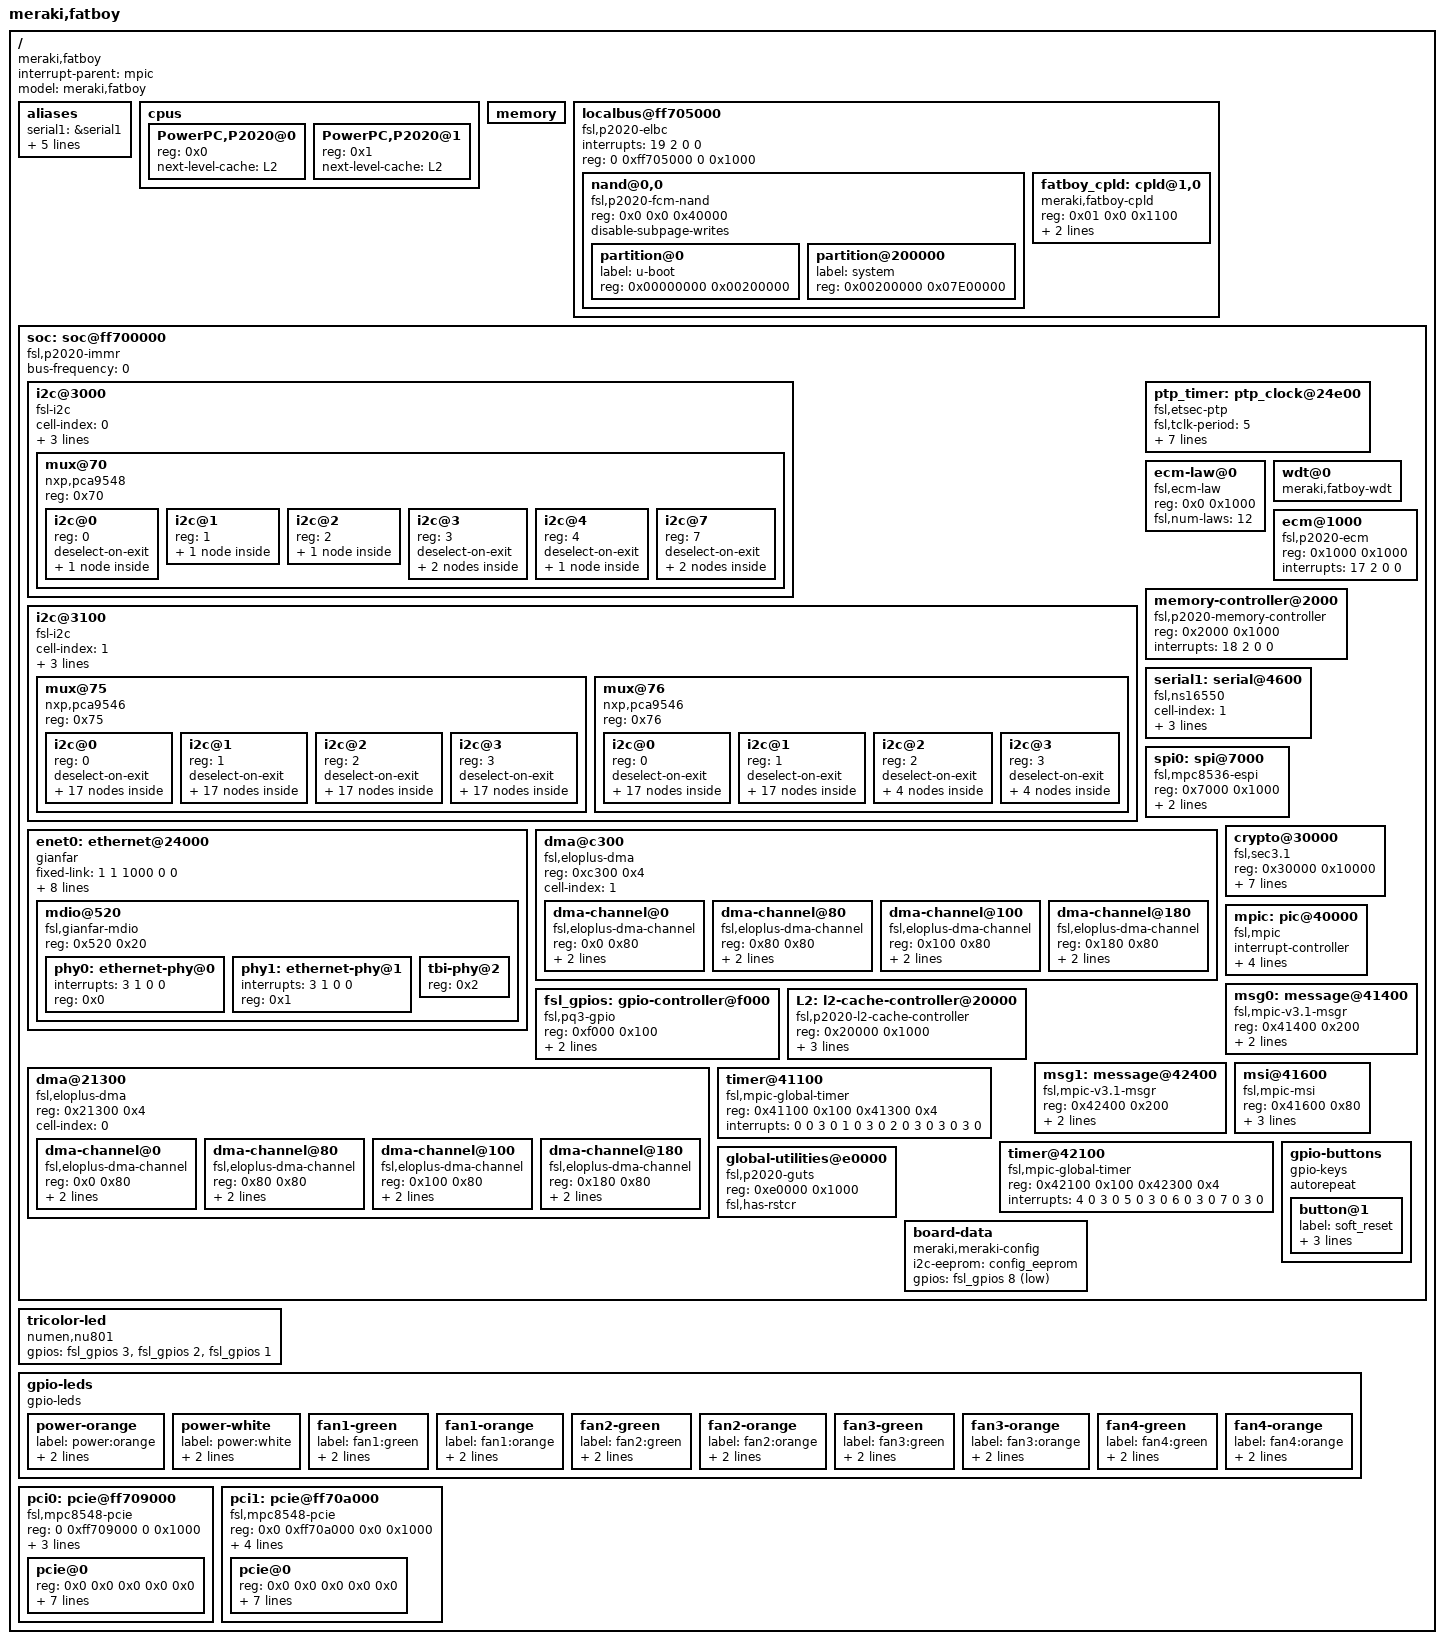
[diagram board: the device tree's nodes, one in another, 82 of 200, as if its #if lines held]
/*
 * Meraki MS420 Series Device Tree Source
 *
 * Copyright 2009-2012 Freescale Semiconductor Inc.
 * Copyright 2013 Cisco Systems, Inc.
 *
 * This program is free software; you can redistribute	it and/or modify it
 * under  the terms of	the GNU General	 Public License as published by the
 * Free Software Foundation;  either version 2 of the  License, or (at your
 * option) any later version.
 */

// Prevent the C preprocessor from expanding the pre-defined "linux" macro.
#ifdef linux
#undef linux
#endif

/dts-v1/;

/ {
	compatible = "meraki,fatboy";
	#address-cells = <2>;
	#size-cells = <2>;
	interrupt-parent = <&mpic>;
	model = "meraki,fatboy";

	aliases {
		serial1 = &serial1;  // U-Boot currently expects this to be aliased as serial1.
		ethernet0 = &enet0;
		pci0 = &pci0;
		pci1 = &pci1;
		mpic-msgr-block0 = &msg0;
		mpic-msgr-block1 = &msg1;
	};

	cpus {
		#address-cells = <1>;
		#size-cells = <0>;

		PowerPC,P2020@0 {
			device_type = "cpu";
			reg = <0x0>;
			next-level-cache = <&L2>;
		};

		PowerPC,P2020@1 {
			device_type = "cpu";
			reg = <0x1>;
			next-level-cache = <&L2>;
		};
	};

	memory {
		device_type = "memory";
	};

	localbus@ff705000 {
		#address-cells = <2>;
		#size-cells = <1>;
		interrupts = <19 2 0 0>;
		reg = <0 0xff705000 0 0x1000>;
		compatible = "fsl,p2020-elbc", "fsl,elbc", "simple-bus";

		ranges = <0x0 0x0 0x0 0xffa00000 0x40000
			  0x1 0x0 0x0 0xea000000 0x01100>;

		nand@0,0 {
			#address-cells = <1>;
			#size-cells = <1>;
			compatible = "fsl,p2020-fcm-nand", "fsl,elbc-fcm-nand";
			reg = <0x0 0x0 0x40000>;
                        disable-subpage-writes;

			partition@0 {
				label = "u-boot";
				reg = <0x00000000 0x00200000>;
			};

			partition@200000 {
				label = "system";
				reg = <0x00200000 0x07E00000>;
			};
                };

		fatboy_cpld: cpld@1,0 {
			compatible = "meraki,fatboy-cpld";
			reg = <0x01 0x0 0x1100>;

                        led-names = "fanstatus:orange", "fanstatus:green", "psu:orange", "psu:green";
		};
	};

	soc: soc@ff700000 {
		ranges = <0x0 0x0 0xff700000 0x100000>;
		#address-cells = <1>;
		#size-cells = <1>;
		device_type = "soc";
		compatible = "fsl,p2020-immr", "simple-bus";
		bus-frequency = <0>;

		i2c@3000 {
			#address-cells = <1>;
			#size-cells = <0>;
			cell-index = <0>;
			compatible = "fsl-i2c";
			reg = <0x3000 0x100>;
			interrupts = <43 2 0 0>;
			dfsrr;

			mux@70 {
				compatible = "nxp,pca9548";
				reg = <0x70>;
				#address-cells = <1>;
				#size-cells = <0>;

				i2c@0 {
					#address-cells = <1>;
					#size-cells = <0>;
					reg = <0>;
					deselect-on-exit;

					rtc@51 {
						compatible = "epson,rtc8564";
						reg = <0x51>;
					};
				};

				i2c@1 {
					#address-cells = <1>;
					#size-cells = <0>;
					reg = <1>;

					psu@3a {
						compatible = "ms420-psu";
						reg = <0x3a>;
						index = <2>;
					};
				};

				i2c@2 {
					#address-cells = <1>;
					#size-cells = <0>;
					reg = <2>;

					psu@39 {
						compatible = "ms420-psu";
						reg = <0x39>;
						index = <1>;
					};
				};

				i2c@3 {
					#address-cells = <1>;
					#size-cells = <0>;
					reg = <3>;
					deselect-on-exit;

					fan_led_gpios: gpio-controller@72 {
						#gpio-cells = <2>;
						compatible = "nxp,pca9538";
						reg = <0x72>;
						gpio-controller;
					};

					fan_dir_gpios: gpio-controller@73 {
						#gpio-cells = <2>;
						compatible = "nxp,pca9538";
						reg = <0x73>;
						gpio-controller;
					};
				};

				i2c@4 {
					#address-cells = <1>;
					#size-cells = <0>;
					reg = <4>;
					deselect-on-exit;

					config_eeprom: at24@50 {
						compatible = "atmel,24c64";
						pagesize = <32>;
						reg = <0x52>;
					};
				};

				i2c@7 {
					#address-cells = <1>;
					#size-cells = <0>;
					reg = <7>;
					deselect-on-exit;

					hwmon@2e {
						compatible = "adi,adt7473";
						reg = <0x2e>;
					};

					temp-sensor@4d {
						compatible = "maxim,max6581";
						alert-bit-mask = <0xFF>;
						over-temperature-mask = <0xFF>;
						reg = <0x4d>;
					};
				};
			};
		};

		i2c@3100 {
			#address-cells = <1>;
			#size-cells = <0>;
			cell-index = <1>;
			compatible = "fsl-i2c";
			reg = <0x3100 0x100>;
			interrupts = <43 2 0 0>;
			dfsrr;

			mux@75 {
				compatible = "nxp,pca9546";
				reg = <0x75>;
				#address-cells = <1>;
				#size-cells = <0>;

#ifdef BOARD_MS420_48
				i2c@0 {
					#address-cells = <1>;
					#size-cells = <0>;
					reg = <0>;
					deselect-on-exit;

					mux@74 {
						compatible = "nxp,pca9548";
						reg = <0x74>;
						#address-cells = <1>;
						#size-cells = <0>;

						i2c@0 {
							#address-cells = <1>;
							#size-cells = <0>;
							reg = <0>;
							deselect-on-exit;
							cell-index = <101>;

							sfp@50 {
								compatible = "sfp-socket";
								reg = <0x50>;
								port = <1>;
								interrupt-parent = <&gpio5>;
								interrupts = <0>;
								gpios = <&gpio1 0 0    // RS0
									 &gpio1 20 0   // RS1
									 &gpio5 0 0    // ABS
									 &gpio7 0 0>;  // RXLOSS
							};
						};

						i2c@1 {
							#address-cells = <1>;
							#size-cells = <0>;
							reg = <1>;
							deselect-on-exit;

							sfp@50 {
								compatible = "sfp-socket";
								reg = <0x50>;
								port = <2>;
								interrupt-parent = <&gpio5>;
								interrupts = <1>;
								gpios = <&gpio1 1 0    // RS0
									 &gpio1 21 0   // RS1
									 &gpio5 1 0    // ABS
									 &gpio7 1 0>;  // RXLOSS
							};
						};

						i2c@2 {
							#address-cells = <1>;
							#size-cells = <0>;
							reg = <2>;
							deselect-on-exit;

							sfp@50 {
								compatible = "sfp-socket";
								reg = <0x50>;
								port = <3>;
								interrupt-parent = <&gpio5>;
								interrupts = <2>;
								gpios = <&gpio1 2 0    // RS0
									 &gpio1 22 0   // RS1
									 &gpio5 2 0    // ABS
									 &gpio7 2 0>;  // RXLOSS
							};
						};

						i2c@3 {
							#address-cells = <1>;
							#size-cells = <0>;
							reg = <3>;
							deselect-on-exit;

							sfp@50 {
								compatible = "sfp-socket";
								reg = <0x50>;
								port = <4>;
								interrupt-parent = <&gpio5>;
								interrupts = <3>;
								gpios = <&gpio1 3 0    // RS0
									 &gpio1 23 0   // RS1
									 &gpio5 3 0    // ABS
									 &gpio7 3 0>;  // RXLOSS
							};
						};

						i2c@4 {
							#address-cells = <1>;
							#size-cells = <0>;
							reg = <4>;
							deselect-on-exit;

							sfp@50 {
								compatible = "sfp-socket";
								reg = <0x50>;
								port = <5>;
								interrupt-parent = <&gpio5>;
								interrupts = <4>;
								gpios = <&gpio1 4 0    // RS0
									 &gpio1 24 0   // RS1
									 &gpio5 4 0    // ABS
									 &gpio7 4 0>;  // RXLOSS
							};
						};

						i2c@5 {
							#address-cells = <1>;
							#size-cells = <0>;
							reg = <5>;
							deselect-on-exit;

							sfp@50 {
								compatible = "sfp-socket";
								reg = <0x50>;
								port = <6>;
								interrupt-parent = <&gpio5>;
								interrupts = <5>;
								gpios = <&gpio1 5 0    // RS0
									 &gpio1 25 0   // RS1
									 &gpio5 5 0    // ABS
									 &gpio7 5 0>;  // RXLOSS
							};
						};

						i2c@6 {
							#address-cells = <1>;
							#size-cells = <0>;
							reg = <6>;
							deselect-on-exit;

							sfp@50 {
								compatible = "sfp-socket";
								reg = <0x50>;
								port = <7>;
								interrupt-parent = <&gpio5>;
								interrupts = <6>;
								gpios = <&gpio1 6 0    // RS0
									 &gpio1 26 0   // RS1
									 &gpio5 6 0    // ABS
									 &gpio7 6 0>;  // RXLOSS
							};
						};

						i2c@7 {
							#address-cells = <1>;
							#size-cells = <0>;
							reg = <7>;
							deselect-on-exit;

							sfp@50 {
								compatible = "sfp-socket";
								reg = <0x50>;
								port = <8>;
								interrupt-parent = <&gpio5>;
								interrupts = <7>;
								gpios = <&gpio1 7 0    // RS0
									 &gpio1 27 0   // RS1
									 &gpio5 7 0    // ABS
									 &gpio7 7 0>;  // RXLOSS
							};
						};
					};
				};

				i2c@1 {
					#address-cells = <1>;
					#size-cells = <0>;
					reg = <1>;
					deselect-on-exit;

					mux@74 {
						compatible = "nxp,pca9548";
						reg = <0x74>;
						#address-cells = <1>;
						#size-cells = <0>;

						i2c@0 {
							#address-cells = <1>;
							#size-cells = <0>;
							reg = <0>;
							deselect-on-exit;

							sfp@50 {
								compatible = "sfp-socket";
								reg = <0x50>;
								port = <9>;
								interrupt-parent = <&gpio5>;
								interrupts = <8>;
								gpios = <&gpio1 8 0    // RS0
									 &gpio1 28 0   // RS1
									 &gpio5 8 0    // ABS
									 &gpio7 8 0>;  // RXLOSS
							};
						};

						i2c@1 {
							#address-cells = <1>;
							#size-cells = <0>;
							reg = <1>;
							deselect-on-exit;

							sfp@50 {
								compatible = "sfp-socket";
								reg = <0x50>;
								port = <10>;
								interrupt-parent = <&gpio5>;
								interrupts = <9>;
								gpios = <&gpio1 9 0    // RS0
									 &gpio1 29 0   // RS1
									 &gpio5 9 0    // ABS
									 &gpio7 9 0>;  // RXLOSS
							};

						};

						i2c@2 {
							#address-cells = <1>;
							#size-cells = <0>;
							reg = <2>;
							deselect-on-exit;

							sfp@50 {
								compatible = "sfp-socket";
								reg = <0x50>;
								port = <11>;
								interrupt-parent = <&gpio5>;
								interrupts = <10>;
								gpios = <&gpio1 10 0   // RS0
									 &gpio1 30 0   // RS1
									 &gpio5 10 0   // ABS
									 &gpio7 10 0>; // RXLOSS
							};
						};

						i2c@3 {
							#address-cells = <1>;
							#size-cells = <0>;
							reg = <3>;
							deselect-on-exit;

							sfp@50 {
								compatible = "sfp-socket";
								reg = <0x50>;
								port = <12>;
								interrupt-parent = <&gpio5>;
								interrupts = <11>;
								gpios = <&gpio1 11 0   // RS0
									 &gpio1 31 0   // RS1
									 &gpio5 11 0   // ABS
									 &gpio7 11 0>; // RXLOSS
							};
						};

						i2c@4 {
							#address-cells = <1>;
							#size-cells = <0>;
							reg = <4>;
							deselect-on-exit;

							sfp@50 {
								compatible = "sfp-socket";
								reg = <0x50>;
								port = <13>;
								interrupt-parent = <&gpio5>;
								interrupts = <12>;
								gpios = <&gpio1 12 0   // RS0
									 &gpio1 32 0   // RS1
									 &gpio5 12 0   // ABS
									 &gpio7 12 0>; // RXLOSS
							};
						};

						i2c@5 {
							#address-cells = <1>;
							#size-cells = <0>;
							reg = <5>;
							deselect-on-exit;

							sfp@50 {
								compatible = "sfp-socket";
								reg = <0x50>;
								port = <14>;
								interrupt-parent = <&gpio5>;
								interrupts = <13>;
								gpios = <&gpio1 13 0   // RS0
									 &gpio1 33 0   // RS1
									 &gpio5 13 0   // ABS
									 &gpio7 13 0>; // RXLOSS
							};
						};

						i2c@6 {
							#address-cells = <1>;
							#size-cells = <0>;
							reg = <6>;
							deselect-on-exit;

							sfp@50 {
								compatible = "sfp-socket";
								reg = <0x50>;
								port = <15>;
								interrupt-parent = <&gpio5>;
								interrupts = <14>;
								gpios = <&gpio1 14 0   // RS0
									 &gpio1 34 0   // RS1
									 &gpio5 14 0   // ABS
									 &gpio7 14 0>; // RXLOSS
							};
						};

						i2c@7 {
							#address-cells = <1>;
							#size-cells = <0>;
							reg = <7>;
							deselect-on-exit;

							sfp@50 {
								compatible = "sfp-socket";
								reg = <0x50>;
								port = <16>;
								interrupt-parent = <&gpio5>;
								interrupts = <15>;
								gpios = <&gpio1 15 0   // RS0
									 &gpio1 35 0   // RS1
									 &gpio5 15 0   // ABS
									 &gpio7 15 0>; // RXLOSS
							};
						};
					};
				};

				i2c@2 {
					#address-cells = <1>;
					#size-cells = <0>;
					reg = <2>;
					deselect-on-exit;

					mux@74 {
						compatible = "nxp,pca9548";
						reg = <0x74>;
						#address-cells = <1>;
						#size-cells = <0>;

						i2c@0 {
							#address-cells = <1>;
							#size-cells = <0>;
							reg = <0>;
							deselect-on-exit;

							sfp@50 {
								compatible = "sfp-socket";
								reg = <0x50>;
								port = <17>;
								interrupt-parent = <&gpio5>;
								interrupts = <16>;
								gpios = <&gpio1 16 0   // RS0
									 &gpio1 36 0   // RS1
									 &gpio5 16 0   // ABS
									 &gpio7 16 0>; // RXLOSS
							};
						};

						i2c@1 {
							#address-cells = <1>;
							#size-cells = <0>;
							reg = <1>;
							deselect-on-exit;

							sfp@50 {
								compatible = "sfp-socket";
								reg = <0x50>;
								port = <18>;
								interrupt-parent = <&gpio5>;
								interrupts = <17>;
								gpios = <&gpio1 17 0   // RS0
									 &gpio1 37 0   // RS1
									 &gpio5 17 0   // ABS
									 &gpio7 17 0>; // RXLOSS
							};
						};

						i2c@2 {
							#address-cells = <1>;
							#size-cells = <0>;
							reg = <2>;
							deselect-on-exit;

							sfp@50 {
								compatible = "sfp-socket";
								reg = <0x50>;
								port = <19>;
								interrupt-parent = <&gpio5>;
								interrupts = <18>;
								gpios = <&gpio1 18 0   // RS0
									 &gpio1 38 0   // RS1
									 &gpio5 18 0   // ABS
									 &gpio7 18 0>; // RXLOSS
							};
						};

						i2c@3 {
							#address-cells = <1>;
							#size-cells = <0>;
							reg = <3>;
							deselect-on-exit;

							sfp@50 {
								compatible = "sfp-socket";
								reg = <0x50>;
								port = <20>;
								interrupt-parent = <&gpio5>;
								interrupts = <19>;
								gpios = <&gpio1 19 0   // RS0
									 &gpio1 39 0   // RS1
									 &gpio5 19 0   // ABS
									 &gpio7 19 0>; // RXLOSS
							};
						};

						i2c@4 {
							#address-cells = <1>;
							#size-cells = <0>;
							reg = <4>;
							deselect-on-exit;

							sfp@50 {
								compatible = "sfp-socket";
								reg = <0x50>;
								port = <21>;
								interrupt-parent = <&gpio5>;
								interrupts = <20>;
								gpios = <&gpio2 0 0    // RS0
									 &gpio2 20 0   // RS1
									 &gpio5 20 0   // ABS
									 &gpio7 20 0>; // RXLOSS
							};
						};

						i2c@5 {
							#address-cells = <1>;
							#size-cells = <0>;
							reg = <5>;
							deselect-on-exit;

							sfp@50 {
								compatible = "sfp-socket";
								reg = <0x50>;
								port = <22>;
								interrupt-parent = <&gpio5>;
								interrupts = <21>;
								gpios = <&gpio2 1 0    // RS0
									 &gpio2 21 0   // RS1
									 &gpio5 21 0   // ABS
									 &gpio7 21 0>; // RXLOSS
							};
						};

						i2c@6 {
							#address-cells = <1>;
							#size-cells = <0>;
							reg = <6>;
							deselect-on-exit;

							sfp@50 {
								compatible = "sfp-socket";
								reg = <0x50>;
								port = <23>;
								interrupt-parent = <&gpio5>;
								interrupts = <22>;
								gpios = <&gpio2 2 0    // RS0
									 &gpio2 22 0   // RS1
									 &gpio5 22 0   // ABS
									 &gpio7 22 0>; // RXLOSS
							};
						};

						i2c@7 {
							#address-cells = <1>;
							#size-cells = <0>;
							reg = <7>;
							deselect-on-exit;

							sfp@50 {
								compatible = "sfp-socket";
								reg = <0x50>;
								port = <24>;
								interrupt-parent = <&gpio5>;
								interrupts = <23>;
								gpios = <&gpio2 3 0    // RS0
									 &gpio2 23 0   // RS1
									 &gpio5 23 0   // ABS
									 &gpio7 23 0>; // RXLOSS
							};
						};
					};
				};
#endif
				i2c@3 {
					#address-cells = <1>;
					#size-cells = <0>;
					reg = <3>;
					deselect-on-exit;

					mux@74 {
						compatible = "nxp,pca9548";
						reg = <0x74>;
						#address-cells = <1>;
						#size-cells = <0>;

						i2c@0 {
							#address-cells = <1>;
							#size-cells = <0>;
							reg = <0>;
							deselect-on-exit;

							sfp@50 {
								compatible = "sfp-socket";
								reg = <0x50>;
#ifdef BOARD_MS420_48
								port = <25>;
#else
								port = <1>;
#endif
								interrupt-parent = <&gpio5>;
								interrupts = <24>;
								gpios = <&gpio2 4 0    // RS0
									 &gpio2 24 0   // RS1
									 &gpio5 24 0   // ABS
									 &gpio7 24 0>; // RXLOSS
							};
						};

						i2c@1 {
							#address-cells = <1>;
							#size-cells = <0>;
							reg = <1>;
							deselect-on-exit;

							sfp@50 {
								compatible = "sfp-socket";
								reg = <0x50>;
#ifdef BOARD_MS420_48
								port = <26>;
#else
								port = <2>;
#endif
								interrupt-parent = <&gpio5>;
								interrupts = <25>;
								gpios = <&gpio2 5 0    // RS0
									 &gpio2 25 0   // RS1
									 &gpio5 25 0   // ABS
									 &gpio7 25 0>; // RXLOSS
							};
						};

						i2c@2 {
							#address-cells = <1>;
							#size-cells = <0>;
							reg = <2>;
							deselect-on-exit;

							sfp@50 {
								compatible = "sfp-socket";
								reg = <0x50>;
#ifdef BOARD_MS420_48
								port = <27>;
#else
								port = <3>;
#endif
								interrupt-parent = <&gpio5>;
								interrupts = <26>;
								gpios = <&gpio2 6 0    // RS0
									 &gpio2 26 0   // RS1
									 &gpio5 26 0   // ABS
									 &gpio7 26 0>; // RXLOSS
							};
						};

						i2c@3 {
							#address-cells = <1>;
							#size-cells = <0>;
							reg = <3>;
							deselect-on-exit;

							sfp@50 {
								compatible = "sfp-socket";
								reg = <0x50>;
#ifdef BOARD_MS420_48
								port = <28>;
#else
								port = <4>;
#endif
								interrupt-parent = <&gpio5>;
								interrupts = <27>;
								gpios = <&gpio2 7 0    // RS0
									 &gpio2 27 0   // RS1
									 &gpio5 27 0   // ABS
									 &gpio7 27 0>; // RXLOSS
							};
						};

						i2c@4 {
							#address-cells = <1>;
							#size-cells = <0>;
							reg = <4>;
							deselect-on-exit;

							sfp@50 {
								compatible = "sfp-socket";
								reg = <0x50>;
#ifdef BOARD_MS420_48
								port = <29>;
#else
								port = <5>;
#endif
								interrupt-parent = <&gpio5>;
								interrupts = <28>;
								gpios = <&gpio2 8 0    // RS0
									 &gpio2 28 0   // RS1
									 &gpio5 28 0   // ABS
									 &gpio7 28 0>; // RXLOSS
							};
						};

						i2c@5 {
							#address-cells = <1>;
							#size-cells = <0>;
							reg = <5>;
							deselect-on-exit;

							sfp@50 {
								compatible = "sfp-socket";
								reg = <0x50>;
#ifdef BOARD_MS420_48
								port = <30>;
#else
								port = <6>;
#endif
								interrupt-parent = <&gpio5>;
								interrupts = <29>;
								gpios = <&gpio2 9 0    // RS0
									 &gpio2 29 0   // RS1
									 &gpio5 29 0   // ABS
									 &gpio7 29 0>; // RXLOSS
							};
						};

						i2c@6 {
							#address-cells = <1>;
							#size-cells = <0>;
							reg = <6>;
							deselect-on-exit;

							sfp@50 {
								compatible = "sfp-socket";
								reg = <0x50>;
#ifdef BOARD_MS420_48
								port = <31>;
#else
								port = <7>;
#endif
								interrupt-parent = <&gpio5>;
								interrupts = <30>;
								gpios = <&gpio2 10 0   // RS0
									 &gpio2 30 0   // RS1
									 &gpio5 30 0   // ABS
									 &gpio7 30 0>; // RXLOSS
							};
						};

						i2c@7 {
							#address-cells = <1>;
							#size-cells = <0>;
							reg = <7>;
							deselect-on-exit;

							sfp@50 {
								compatible = "sfp-socket";
								reg = <0x50>;
#ifdef BOARD_MS420_48
								port = <32>;
#else
								port = <8>;
#endif
								interrupt-parent = <&gpio5>;
								interrupts = <31>;
								gpios = <&gpio2 11 0   // RS0
									 &gpio2 31 0   // RS1
									 &gpio5 31 0   // ABS
									 &gpio7 31 0>; // RXLOSS
							};
						};
					};
				};
			};


			mux@76 {
				compatible = "nxp,pca9546";
				reg = <0x76>;
				#address-cells = <1>;
				#size-cells = <0>;

				i2c@0 {
					#address-cells = <1>;
					#size-cells = <0>;
					reg = <0>;
					deselect-on-exit;

					mux@75 {
						compatible = "nxp,pca9548";
						reg = <0x74>;
						#address-cells = <1>;
						#size-cells = <0>;

						i2c@0 {
							#address-cells = <1>;
							#size-cells = <0>;
							reg = <0>;
							deselect-on-exit;

							sfp@50 {
								compatible = "sfp-socket";
								reg = <0x50>;
#ifdef BOARD_MS420_48
								port = <33>;
#else
								port = <9>;
#endif
								interrupt-parent = <&gpio5>;
								interrupts = <32>;
								gpios = <&gpio2 12 0   // RS0
									 &gpio2 32 0   // RS1
									 &gpio5 32 0   // ABS
									 &gpio7 32 0>; // RXLOSS
							};
						};

						i2c@1 {
							#address-cells = <1>;
							#size-cells = <0>;
							reg = <1>;
							deselect-on-exit;

							sfp@50 {
								compatible = "sfp-socket";
								reg = <0x50>;
#ifdef BOARD_MS420_48
								port = <34>;
#else
								port = <10>;
#endif
								interrupt-parent = <&gpio5>;
								interrupts = <33>;
								gpios = <&gpio2 13 0   // RS0
									 &gpio2 33 0   // RS1
									 &gpio5 33 0   // ABS
									 &gpio7 33 0>; // RXLOSS
							};
						};

						i2c@2 {
							#address-cells = <1>;
							#size-cells = <0>;
							reg = <2>;
							deselect-on-exit;

							sfp@50 {
								compatible = "sfp-socket";
								reg = <0x50>;
#ifdef BOARD_MS420_48
								port = <35>;
#else
								port = <11>;
#endif
								interrupt-parent = <&gpio5>;
								interrupts = <34>;
								gpios = <&gpio2 14 0   // RS0
									 &gpio2 34 0   // RS1
									 &gpio5 34 0   // ABS
									 &gpio7 34 0>; // RXLOSS
							};
						};

						i2c@3 {
							#address-cells = <1>;
							#size-cells = <0>;
							reg = <3>;
							deselect-on-exit;

							sfp@50 {
								compatible = "sfp-socket";
								reg = <0x50>;
#ifdef BOARD_MS420_48
								port = <36>;
#else
								port = <12>;
#endif
								interrupt-parent = <&gpio5>;
								interrupts = <35>;
								gpios = <&gpio2 15 0   // RS0
									 &gpio2 35 0   // RS1
									 &gpio5 35 0   // ABS
									 &gpio7 35 0>; // RXLOSS
							};
						};

						i2c@4 {
							#address-cells = <1>;
							#size-cells = <0>;
							reg = <4>;
							deselect-on-exit;

							sfp@50 {
								compatible = "sfp-socket";
								reg = <0x50>;
#ifdef BOARD_MS420_48
								port = <37>;
#else
								port = <13>;
#endif
								interrupt-parent = <&gpio5>;
								interrupts = <36>;
								gpios = <&gpio2 16 0   // RS0
									 &gpio2 36 0   // RS1
									 &gpio5 36 0   // ABS
									 &gpio7 36 0>; // RXLOSS
							};
						};

						i2c@5 {
							#address-cells = <1>;
							#size-cells = <0>;
							reg = <5>;
							deselect-on-exit;

							sfp@50 {
								compatible = "sfp-socket";
								reg = <0x50>;
#ifdef BOARD_MS420_48
								port = <38>;
#else
								port = <14>;
#endif
								interrupt-parent = <&gpio5>;
								interrupts = <37>;
								gpios = <&gpio2 17 0   // RS0
									 &gpio2 37 0   // RS1
									 &gpio5 37 0   // ABS
									 &gpio7 37 0>; // RXLOSS
							};
						};

						i2c@6 {
							#address-cells = <1>;
							#size-cells = <0>;
							reg = <6>;
							deselect-on-exit;

							sfp@50 {
								compatible = "sfp-socket";
								reg = <0x50>;
#ifdef BOARD_MS420_48
								port = <39>;
#else
								port = <15>;
#endif
								interrupt-parent = <&gpio5>;
								interrupts = <38>;
								gpios = <&gpio2 18 0   // RS0
									 &gpio2 38 0   // RS1
									 &gpio5 38 0   // ABS
									 &gpio7 38 0>; // RXLOSS
							};
						};

						i2c@7 {
							#address-cells = <1>;
							#size-cells = <0>;
							reg = <7>;
							deselect-on-exit;

							sfp@50 {
								compatible = "sfp-socket";
								reg = <0x50>;
#ifdef BOARD_MS420_48
								port = <40>;
#else
								port = <16>;
#endif
								interrupt-parent = <&gpio5>;
								interrupts = <39>;
								gpios = <&gpio2 19 0   // RS0
									 &gpio2 39 0   // RS1
									 &gpio5 39 0   // ABS
									 &gpio7 39 0>; // RXLOSS
							};
						};
					};
				};

				i2c@1 {
					#address-cells = <1>;
					#size-cells = <0>;
					reg = <1>;
					deselect-on-exit;

					mux@75 {
						compatible = "nxp,pca9548";
						reg = <0x74>;
						#address-cells = <1>;
						#size-cells = <0>;

						i2c@0 {
							#address-cells = <1>;
							#size-cells = <0>;
							reg = <0>;
							deselect-on-exit;

							sfp@50 {
								compatible = "sfp-socket";
								reg = <0x50>;
#ifdef BOARD_MS420_48
								port = <41>;
#else
								port = <17>;
#endif
								interrupt-parent = <&gpio6>;
								interrupts = <0>;
								gpios = <&gpio3 0 0    // RS0
									 &gpio4 0 0    // RS1
									 &gpio6 0 0    // ABS
									 &gpio8 0 0>;  // RXLOSS
							};
						};

						i2c@1 {
							#address-cells = <1>;
							#size-cells = <0>;
							reg = <1>;
							deselect-on-exit;

							sfp@50 {
								compatible = "sfp-socket";
								reg = <0x50>;
#ifdef BOARD_MS420_48
								port = <42>;
#else
								port = <18>;
#endif
								interrupt-parent = <&gpio6>;
								interrupts = <1>;
								gpios = <&gpio3 1 0    // RS0
									 &gpio4 1 0    // RS1
									 &gpio6 1 0    // ABS
									 &gpio8 1 0>;  // RXLOSS
							};
						};

						i2c@2 {
							#address-cells = <1>;
							#size-cells = <0>;
							reg = <2>;
							deselect-on-exit;

							sfp@50 {
								compatible = "sfp-socket";
								reg = <0x50>;
#ifdef BOARD_MS420_48
								port = <43>;
#else
								port = <19>;
#endif
								interrupt-parent = <&gpio6>;
								interrupts = <2>;
								gpios = <&gpio3 2 0    // RS0
									 &gpio4 2 0    // RS1
									 &gpio6 2 0    // ABS
									 &gpio8 2 0>;  // RXLOSS
							};
						};

						i2c@3 {
							#address-cells = <1>;
							#size-cells = <0>;
							reg = <3>;
							deselect-on-exit;

							sfp@50 {
								compatible = "sfp-socket";
								reg = <0x50>;
#ifdef BOARD_MS420_48
								port = <44>;
#else
								port = <20>;
#endif
								interrupt-parent = <&gpio6>;
								interrupts = <3>;
								gpios = <&gpio3 3 0    // RS0
									 &gpio4 3 0    // RS1
									 &gpio6 3 0    // ABS
									 &gpio8 3 0>;  // RXLOSS
							};
						};

						i2c@4 {
							#address-cells = <1>;
							#size-cells = <0>;
							reg = <4>;
							deselect-on-exit;

							sfp@50 {
								compatible = "sfp-socket";
								reg = <0x50>;
#ifdef BOARD_MS420_48
								port = <45>;
#else
								port = <21>;
#endif
								interrupt-parent = <&gpio6>;
								interrupts = <4>;
								gpios = <&gpio3 4 0    // RS0
									 &gpio4 4 0    // RS1
									 &gpio6 4 0    // ABS
									 &gpio8 4 0>;  // RXLOSS
							};
						};

						i2c@5 {
							#address-cells = <1>;
							#size-cells = <0>;
							reg = <5>;
							deselect-on-exit;

							sfp@50 {
								compatible = "sfp-socket";
								reg = <0x50>;
#ifdef BOARD_MS420_48
								port = <46>;
#else
								port = <22>;
#endif
								interrupt-parent = <&gpio6>;
								interrupts = <5>;
								gpios = <&gpio3 5 0    // RS0
									 &gpio4 5 0    // RS1
									 &gpio6 5 0    // ABS
									 &gpio8 5 0>;  // RXLOSS
							};
						};

						i2c@6 {
							#address-cells = <1>;
							#size-cells = <0>;
							reg = <6>;
							deselect-on-exit;

							sfp@50 {
								compatible = "sfp-socket";
								reg = <0x50>;
#ifdef BOARD_MS420_48
								port = <47>;
#else
								port = <23>;
#endif
								interrupt-parent = <&gpio6>;
								interrupts = <6>;
								gpios = <&gpio3 6 0    // RS0
									 &gpio4 6 0    // RS1
									 &gpio6 6 0    // ABS
									 &gpio8 6 0>;  // RXLOSS
							};
						};

						i2c@7 {
							#address-cells = <1>;
							#size-cells = <0>;
							reg = <7>;
							deselect-on-exit;

							sfp@50 {
								compatible = "sfp-socket";
								reg = <0x50>;
#ifdef BOARD_MS420_48
								port = <48>;
#else
								port = <24>;
#endif
								interrupt-parent = <&gpio6>;
								interrupts = <7>;
								gpios = <&gpio3 7 0    // RS0
									 &gpio4 7 0    // RS1
									 &gpio6 7 0    // ABS
									 &gpio8 7 0>;  // RXLOSS
							};
						};
					};
				};

				i2c@2 {
					#address-cells = <1>;
					#size-cells = <0>;
					reg = <2>;
					deselect-on-exit;

#ifdef BOARD_MS420_48
					// SFP RS0/RS1 ports 1-20
					gpio1: gpio-controller@20 {
						#gpio-cells = <2>;
						compatible = "nxp,pca9505";
						reg = <0x20>;
						gpio-controller;
					};
#endif
					// SFP RS0/RS1 ports 21-40
					gpio2: gpio-controller@21 {
						#gpio-cells = <2>;
						compatible = "nxp,pca9505";
						reg = <0x21>;
						gpio-controller;
					};

					// SFP RS0 ports 41-48
					gpio3: gpio-controller@72 {
						#gpio-cells = <2>;
						compatible = "nxp,pca9538";
						reg = <0x72>;
						gpio-controller;
					};

					// SFP RS1 ports 41-48
					gpio4: gpio-controller@73 {
						#gpio-cells = <2>;
						compatible = "nxp,pca9538";
						reg = <0x73>;
						gpio-controller;
					};

				};

				i2c@3 {
					#address-cells = <1>;
					#size-cells = <0>;
					reg = <3>;
					deselect-on-exit;

					// SFP_ABS ports 1-40
					gpio5: gpio-controller@20 {
						#gpio-cells = <2>;
						compatible = "nxp,pca9505";
						reg = <0x20>;
						interrupts = <6 1 0 0>;
						gpio-controller;
						interrupt-controller;
						#interrupt-cells = <1>;
					};

					// SFP_ABS ports 41-48
					gpio6: gpio-controller@71 {
						#gpio-cells = <2>;
						compatible = "nxp,pca9538";
						reg = <0x71>;
						gpio-controller;
						interrupts = <6 1 0 0>;
						interrupt-controller;
						#interrupt-cells = <1>;
					};

					// SFP_LOS ports 1-40
					// We're not using the LOS interrupt now, so
					// I'm leaving the interrupt config out.  This
					// should cause the interrupts to be masked.
					gpio7: gpio-controller@22 {
						#gpio-cells = <2>;
						compatible = "nxp,pca9505";
						reg = <0x22>;
						gpio-controller;
					};

					// SFP_LOS ports 41-48
					// Unlike the PCA9506, the PCA9538 does not
					// have an interrupt mask. So we'll have to
					// service the interrupt even though we're not
					// using it.
					gpio8: gpio-controller@73 {
						#gpio-cells = <2>;
						compatible = "nxp,pca9538";
						reg = <0x73>;
						gpio-controller;
						interrupts = <6 1 0 0>;
						interrupt-controller;
						#interrupt-cells = <1>;
					};
				};
			};
		};

		ptp_timer: ptp_clock@24e00 {
			fsl,tclk-period = <5>;
			fsl,tmr-prsc = <200>;
			fsl,tmr-add = <0xcccccccd>;
			fsl,tmr-fiper1 = <0x3b9ac9fb>;
			fsl,tmr-fiper2 = <0x1869b>;
			fsl,max-adj = <0xee6b27f>;
			compatible = "fsl,etsec-ptp";
			reg = <0x24e00 0xb0>;
			interrupts = <
				68 2 0 0
 				69 2 0 0
				70 2 0 0>;
		};

		enet0: ethernet@24000 {
			fixed-link = <1 1 1000 0 0>;
			phy-connection-type = "rgmii-id";
			#address-cells = <1>;
			#size-cells = <1>;
			cell-index = <0>;
			device_type = "network";
			model = "eTSEC";
			compatible = "gianfar";
			reg = <0x24000 0x1000>;
			ranges = <0 0x24000 0x1000>;
			fsl,magic-packet;
			local-mac-address = [00 00 00 00 00 00];
			ptimer-handle = <&ptp_timer>;
			interrupts = <
				29 2 0 0
				30 2 0 0
				34 2 0 0>;

			mdio@520 {
				#address-cells = <1>;
				#size-cells = <0>;
				compatible = "fsl,gianfar-mdio";
				reg = <0x520 0x20>;

				phy0: ethernet-phy@0 {
					interrupts = <3 1 0 0>;
					reg = <0x0>;
				};

				phy1: ethernet-phy@1 {
					interrupts = <3 1 0 0>;
					reg = <0x1>;
				};

				tbi-phy@2 {
					device_type = "tbi-phy";
					reg = <0x2>;
				};
			};
		};

		ecm-law@0 {
			compatible = "fsl,ecm-law";
			reg = <0x0 0x1000>;
			fsl,num-laws = <12>;
		};

		wdt@0 {
			compatible = "meraki,fatboy-wdt";
		};

		ecm@1000 {
			compatible = "fsl,p2020-ecm", "fsl,ecm";
			reg = <0x1000 0x1000>;
			interrupts = <17 2 0 0>;
		};

		memory-controller@2000 {
			compatible = "fsl,p2020-memory-controller";
			reg = <0x2000 0x1000>;
			interrupts = <18 2 0 0>;
		};

		serial1: serial@4600 {
			cell-index = <1>;
			device_type = "serial";
			compatible = "fsl,ns16550", "ns16550";
			reg = <0x4600 0x100>;
			clock-frequency = <0>;
			interrupts = <42 2 0 0>;
		};

		spi0: spi@7000 {
			#address-cells = <1>;
			#size-cells = <0>;
			compatible = "fsl,mpc8536-espi";
			reg = <0x7000 0x1000>;
			interrupts = <59 2 0 0>;
			fsl,espi-num-chipselects = <4>;
		};

		dma@c300 {
			#address-cells = <1>;
			#size-cells = <1>;
			compatible = "fsl,eloplus-dma";
			reg = <0xc300 0x4>;
			ranges = <0x0 0xc100 0x200>;
			cell-index = <1>;

			dma-channel@0 {
				compatible = "fsl,eloplus-dma-channel";
				reg = <0x0 0x80>;
				cell-index = <0>;
				interrupts = <76 2 0 0>;
			};

			dma-channel@80 {
				compatible = "fsl,eloplus-dma-channel";
				reg = <0x80 0x80>;
				cell-index = <1>;
				interrupts = <77 2 0 0>;
			};

			dma-channel@100 {
				compatible = "fsl,eloplus-dma-channel";
				reg = <0x100 0x80>;
				cell-index = <2>;
				interrupts = <78 2 0 0>;
			};

			dma-channel@180 {
				compatible = "fsl,eloplus-dma-channel";
				reg = <0x180 0x80>;
				cell-index = <3>;
				interrupts = <79 2 0 0>;
			};
		};

		fsl_gpios: gpio-controller@f000 {
			#gpio-cells = <2>;
			compatible = "fsl,pq3-gpio";
			reg = <0xf000 0x100>;
			interrupts = <47 2 0 0>;
			gpio-controller;
		};

		L2: l2-cache-controller@20000 {
			compatible = "fsl,p2020-l2-cache-controller";
			reg = <0x20000 0x1000>;
			cache-line-size = <32>;
			cache-size = <0x80000>;
			interrupts = <16 2 0 0>;
		};

		dma@21300 {
			#address-cells = <1>;
			#size-cells = <1>;
			compatible = "fsl,eloplus-dma";
			reg = <0x21300 0x4>;
			ranges = <0x0 0x21100 0x200>;
			cell-index = <0>;

			dma-channel@0 {
				compatible = "fsl,eloplus-dma-channel";
				reg = <0x0 0x80>;
				cell-index = <0>;
				interrupts = <20 2 0 0>;
			};

			dma-channel@80 {
				compatible = "fsl,eloplus-dma-channel";
				reg = <0x80 0x80>;
				cell-index = <1>;
				interrupts = <21 2 0 0>;
			};

			dma-channel@100 {
				compatible = "fsl,eloplus-dma-channel";
				reg = <0x100 0x80>;
				cell-index = <2>;
				interrupts = <22 2 0 0>;
			};

			dma-channel@180 {
				compatible = "fsl,eloplus-dma-channel";
				reg = <0x180 0x80>;
				cell-index = <3>;
				interrupts = <23 2 0 0>;
			};
		};

		crypto@30000 {
			compatible = "fsl,sec3.1", "fsl,sec3.0", "fsl,sec2.4",
				     "fsl,sec2.2", "fsl,sec2.1", "fsl,sec2.0";
			reg = <0x30000 0x10000>;
			interrupts = <
				45 2 0 0
				58 2 0 0>;
			fsl,num-channels = <4>;
			fsl,channel-fifo-len = <24>;
			fsl,exec-units-mask = <0xbfe>;
			fsl,descriptor-types-mask = <0x3ab0ebf>;
			fsl,multi-host-mode = "dual";
			fsl,channel-remap = <3>;
		};

		mpic: pic@40000 {
			interrupt-controller;
			#address-cells = <0>;
			#interrupt-cells = <4>;
			reg = <0x40000 0x40000>;
			compatible = "fsl,mpic";
			device_type = "open-pic";
			big-endian;
			single-cpu-affinity;
			last-interrupt-source = <0xff>;
		};

		msg0: message@41400 {
			compatible = "fsl,mpic-v3.1-msgr";
			reg = <0x41400 0x200>;
			interrupts = <
				0xb0 2 0 0
				0xb1 2 0 0
				0xb2 2 0 0
				0xb3 2 0 0>;
		};
		msg1: message@42400 {
			compatible = "fsl,mpic-v3.1-msgr";
			reg = <0x42400 0x200>;
			interrupts = <
				0xb4 2 0 0
				0xb5 2 0 0
				0xb6 2 0 0
				0xb7 2 0 0>;
		};

		msi@41600 {
			compatible = "fsl,mpic-msi";
			reg = <0x41600 0x80>;
			msi-available-ranges = <0x0 0x100>;
			interrupts = <
				0xe0 0 0 0
				0xe1 0 0 0
				0xe2 0 0 0
				0xe3 0 0 0
				0xe4 0 0 0
				0xe5 0 0 0
				0xe6 0 0 0
				0xe7 0 0 0>;
		};

		timer@41100 {
			compatible = "fsl,mpic-global-timer";
			reg = <0x41100 0x100 0x41300 0x4>;
			interrupts = <
				0 0 3 0
				1 0 3 0
				2 0 3 0
				3 0 3 0>;
		};

		timer@42100 {
			compatible = "fsl,mpic-global-timer";
			reg = <0x42100 0x100 0x42300 0x4>;
			interrupts = <
				4 0 3 0
				5 0 3 0
				6 0 3 0
				7 0 3 0>;
		};

		global-utilities@e0000 {
			compatible = "fsl,p2020-guts";
			reg = <0xe0000 0x1000>;
			fsl,has-rstcr;
		};

		board-data {
			compatible = "meraki,meraki-config";
			i2c-eeprom = <&config_eeprom>;
			gpios = <&fsl_gpios 8 1>;
		};

		gpio-buttons {
			compatible = "gpio-keys";
			#address-cells = <1>;
			#size-cells = <0>;
			autorepeat;
			button@1 {
				label = "soft_reset";
				linux,code = <0x198>;     // EV_RESTART
                                linux,input-type = <1>;   // EV_KEY
				gpios = <&fsl_gpios 0 1>;
			};
		};
	};

	tricolor-led {
		compatible = "numen,nu801";
		gpios = <&fsl_gpios 3 0	   // CKI
			 &fsl_gpios 2 0	   // SDI
			 &fsl_gpios 1 0>;  // LEI
	};

	gpio-leds {
		compatible = "gpio-leds";
		power-orange {
			label = "power:orange";
			gpios = <&fsl_gpios 5 0>;
			default-state = "on";
		};

		power-white {
			label = "power:white";
			gpios = <&fsl_gpios 4 0>;
			default-state = "off";
		};

		fan1-green {
			label = "fan1:green";
			gpios = <&fan_led_gpios 0 1>;
			default-state = "off";
		};

		fan1-orange {
			label = "fan1:orange";
			gpios = <&fan_led_gpios 1 1>;
			default-state = "off";
		};

		fan2-green {
			label = "fan2:green";
			gpios = <&fan_led_gpios 2 1>;
			default-state = "off";
		};

		fan2-orange {
			label = "fan2:orange";
			gpios = <&fan_led_gpios 3 1>;
			default-state = "off";
		};

		fan3-green {
			label = "fan3:green";
			gpios = <&fan_led_gpios 4 1>;
			default-state = "off";
		};

		fan3-orange {
			label = "fan3:orange";
			gpios = <&fan_led_gpios 5 1>;
			default-state = "off";
		};

		fan4-green {
			label = "fan4:green";
			gpios = <&fan_led_gpios 6 1>;
			default-state = "off";
		};

		fan4-orange {
			label = "fan4:orange";
			gpios = <&fan_led_gpios 7 1>;
			default-state = "off";
		};
	};

	pci0: pcie@ff709000 {
		reg = <0 0xff709000 0 0x1000>;
		ranges = <0x2000000 0x0 0xc0000000 0 0xc0000000 0x0 0x20000000
			  0x1000000 0x0 0x00000000 0 0xffc30000 0x0 0x10000>;
		compatible = "fsl,mpc8548-pcie";
		device_type = "pci";
		#size-cells = <2>;
		#address-cells = <3>;
		bus-range = <0 255>;
		clock-frequency = <33333333>;
		interrupts = <25 2 0 0>;

		pcie@0 {
			ranges = <0x2000000 0x0 0xc0000000
				  0x2000000 0x0 0xc0000000
				  0x0 0x20000000

				  0x1000000 0x0 0x0
				  0x1000000 0x0 0x0
				  0x0 0x100000>;
			reg = <0x0 0x0 0x0 0x0 0x0>;
			#interrupt-cells = <1>;
			#size-cells = <2>;
			#address-cells = <3>;
			device_type = "pci";
			interrupts = <25 2 0 0>;
			interrupt-map-mask = <0xf800 0x0 0x0 0x7>;
			interrupt-map = <
				0000 0x0 0x0 0x1 &mpic 0x4 0x1 0x0 0x0
				0000 0x0 0x0 0x2 &mpic 0x5 0x1 0x0 0x0
				0000 0x0 0x0 0x3 &mpic 0x6 0x1 0x0 0x0
				0000 0x0 0x0 0x4 &mpic 0x7 0x1 0x0 0x0>;
		};
	};

	pci1: pcie@ff70a000 {
		reg = <0x0 0xff70a000 0x0 0x1000>;
		ranges = <0x2000000 0x0 0xa0000000 0x0 0xa0000000 0x0 0x20000000
			  0x1000000 0x0 0x00000000 0x0 0xffc20000 0x0 0x10000>;
		compatible = "fsl,mpc8548-pcie";
		device_type = "pci";
		#size-cells = <2>;
		#address-cells = <3>;
		bus-range = <0 255>;
		clock-frequency = <33333333>;
		interrupts = <26 2 0 0>;
		max-payload-size = <256>;

		pcie@0 {
			ranges = <0x2000000 0x0 0xc0000000
				  0x2000000 0x0 0xc0000000
				  0x0 0x20000000

				  0x1000000 0x0 0x0
				  0x1000000 0x0 0x0
				  0x0 0x100000>;
			reg = <0x0 0x0 0x0 0x0 0x0>;
			#interrupt-cells = <1>;
			#size-cells = <2>;
			#address-cells = <3>;
			device_type = "pci";
			interrupts = <26 2 0 0>;
			interrupt-map-mask = <0xf800 0x0 0x0 0x7>;
			interrupt-map = <
				0000 0x0 0x0 0x1 &mpic 0x0 0x1 0x0 0x0
				0000 0x0 0x0 0x2 &mpic 0x1 0x1 0x0 0x0
				0000 0x0 0x0 0x3 &mpic 0x2 0x1 0x0 0x0
				0000 0x0 0x0 0x4 &mpic 0x3 0x1 0x0 0x0>;
		};
	};
};
